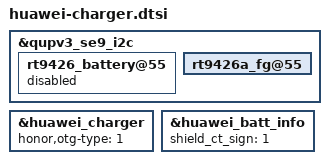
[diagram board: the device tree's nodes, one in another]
&qupv3_se9_i2c {
	rt9426_battery@55{
		status = "disabled";
	};

	rt9426a_fg@55 {
		status = "ok";
	};
};

&huawei_charger {
	honor,otg-type = <1>;
};

&huawei_batt_info {
	status = "ok";
	shield_ct_sign = <1>;
};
